# STM32F303 register map
File version: 1.8
CPU: CM4 r1p0, little endian, MPU, FPU, 4 interrupt priority bits
Registers are 32-bit, read-write, reset 0x0 unless marked. A register's access mark holds for its fields unless they carry their own. Offsets are from the block's base; [hi:lo] are bit positions; {n}, {i} and the like mark numbered series; 'fields as' and 'values as' point back to an identical list.

## EXTI — External interrupt/event controller
Base 0x40010400
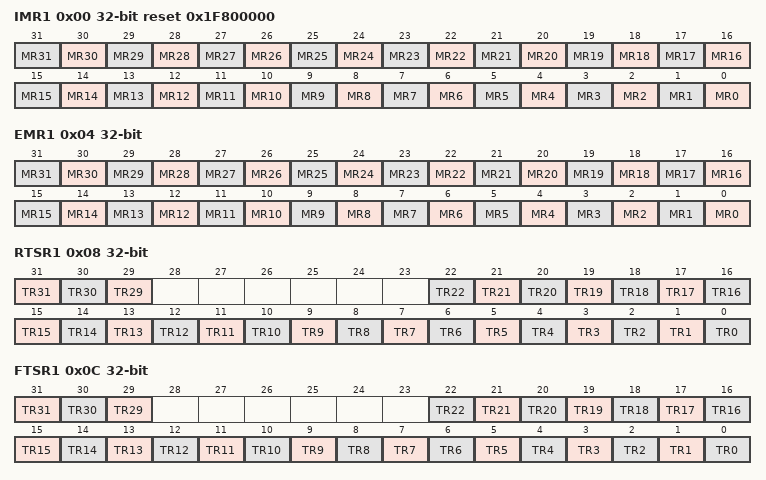
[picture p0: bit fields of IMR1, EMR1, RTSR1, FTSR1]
0x00 IMR1 reset 0x1F800000 — Interrupt mask register
  [all] fields
    0=Masked (Interrupt request line is masked); 1=Unmasked (Interrupt request line is unmasked)
  [n] MR{n} (n=0..31) — Interrupt Mask on line {n}
0x04 EMR1 — Event mask register
  [all] fields
    0=Masked (Event request line is masked); 1=Unmasked (Event request line is unmasked)
  [n] MR{n} (n=0..31) — Event Mask on line {n}
0x08 RTSR1 — Rising Trigger selection register
  [all] fields
    0=Disabled (Rising edge trigger is disabled); 1=Enabled (Rising edge trigger is enabled)
  [31] TR31 — Rising trigger event configuration of line 31
  [30] TR30 — Rising trigger event configuration of line 30
  [29] TR29 — Rising trigger event configuration of line 29
  [n] TR{n} (n=0..22) — Rising trigger event configuration of line {n}
0x0C FTSR1 — Falling Trigger selection register
  [all] fields
    0=Disabled (Falling edge trigger is disabled); 1=Enabled (Falling edge trigger is enabled)
  [31] TR31 — Falling trigger event configuration of line 31
  [30] TR30 — Falling trigger event configuration of line 30.
  [29] TR29 — Falling trigger event configuration of line 29
  [n] TR{n} (n=0..22) — Falling trigger event configuration of line {n}
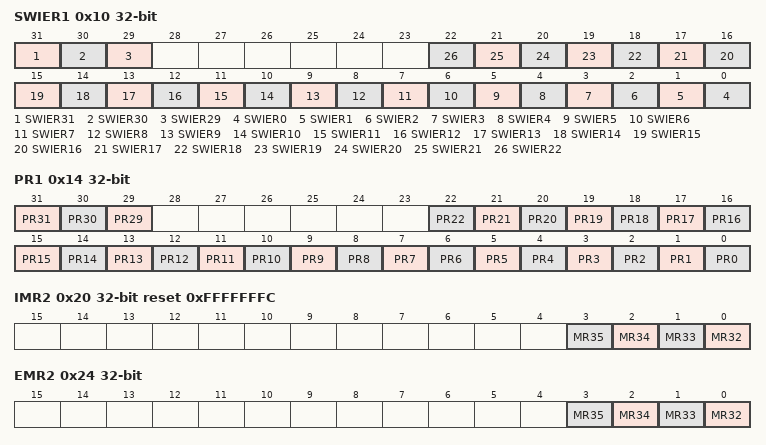
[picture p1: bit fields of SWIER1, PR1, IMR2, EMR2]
0x10 SWIER1 — Software interrupt event register
  [all] fields
    on write: 1=Pend (Generates an interrupt request)
  [31] SWIER31 — Software Interrupt on line 319
  [30] SWIER30 — Software Interrupt on line 309
  [29] SWIER29 — Software Interrupt on line 29
  [n] SWIER{n} (n=0..22) — Software Interrupt on line {n}
0x14 PR1 — Pending register
  [all] fields
    on read: 0=NotPending (No trigger request occurred); 1=Pending (Selected trigger request occurred) | on write: 1=Clears pending bit
  [31] PR31 write-1-clears — Pending bit 31
  [30] PR30 write-1-clears — Pending bit 30
  [29] PR29 write-1-clears — Pending bit 29
  [n] PR{n} write-1-clears (n=0..22) — Pending bit {n}
0x20 IMR2 reset 0xFFFFFFFC — Interrupt mask register
  [all] fields
    values as the fields of IMR1
  [n-32] MR{n} (n=32..35) — Interrupt Mask on external/internal line {n}
0x24 EMR2 — Event mask register
  [all] fields
    values as the fields of EMR1
  [n-32] MR{n} (n=32..35) — Event mask on external/internal line {n}
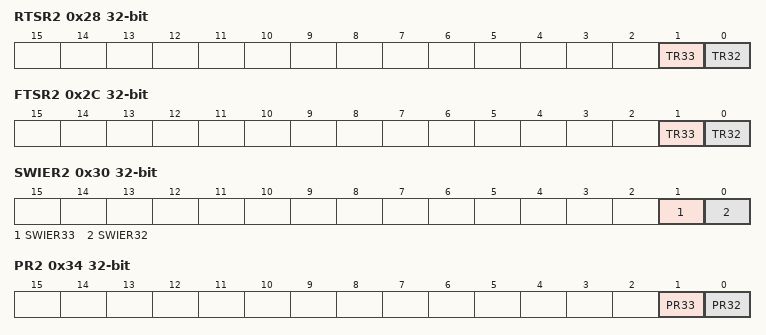
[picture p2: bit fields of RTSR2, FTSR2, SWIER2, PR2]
0x28 RTSR2 — Rising Trigger selection register
  [1] TR33 — Rising trigger event configuration bit of line 33
    values as the fields of RTSR1
  [0] TR32 — Rising trigger event configuration bit of line 32
    values as the fields of RTSR1
0x2C FTSR2 — Falling Trigger selection register
  [1] TR33 — Falling trigger event configuration bit of line 33
    values as the fields of FTSR1
  [0] TR32 — Falling trigger event configuration bit of line 32
    values as the fields of FTSR1
0x30 SWIER2 — Software interrupt event register
  [1] SWIER33 — Software interrupt on line 33
    on write: 1=Pend (Generates an interrupt request)
  [0] SWIER32 — Software interrupt on line 32
    on write: 1=Pend (Generates an interrupt request)
0x34 PR2 — Pending register
  [1] PR33 write-1-clears — Pending bit on line 33
    values as the fields of PR1
  [0] PR32 write-1-clears — Pending bit on line 32
    values as the fields of PR1

## PWR — Power control
Base 0x40007000
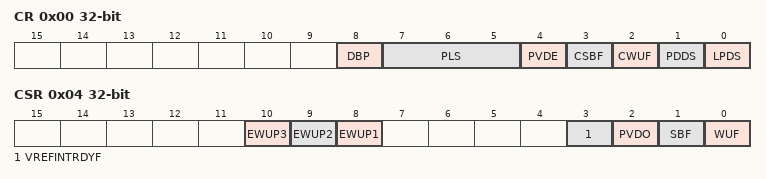
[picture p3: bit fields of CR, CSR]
0x00 CR — power control register
  [8] DBP — Disable backup domain write protection
  [7:5] PLS — PVD level selection
  [4] PVDE — Power voltage detector enable
  [3] CSBF — Clear standby flag
  [2] CWUF — Clear wakeup flag
  [1] PDDS — Power down deepsleep
    0=STOP_MODE (Enter Stop mode when the CPU enters deepsleep); 1=STANDBY_MODE (Enter Standby mode when the CPU enters deepsleep)
  [0] LPDS — Low-power deep sleep
0x04 CSR access per field — power control/status register
  [10] EWUP3 rw — Enable WKUP3 pin
  [9] EWUP2 rw — Enable WKUP2 pin
  [8] EWUP1 rw — Enable WKUP1 pin
  [3] VREFINTRDYF ro — Internal voltage reference ready flag
  [2] PVDO ro — PVD output
  [1] SBF ro — Standby flag
  [0] WUF ro — Wakeup flag
